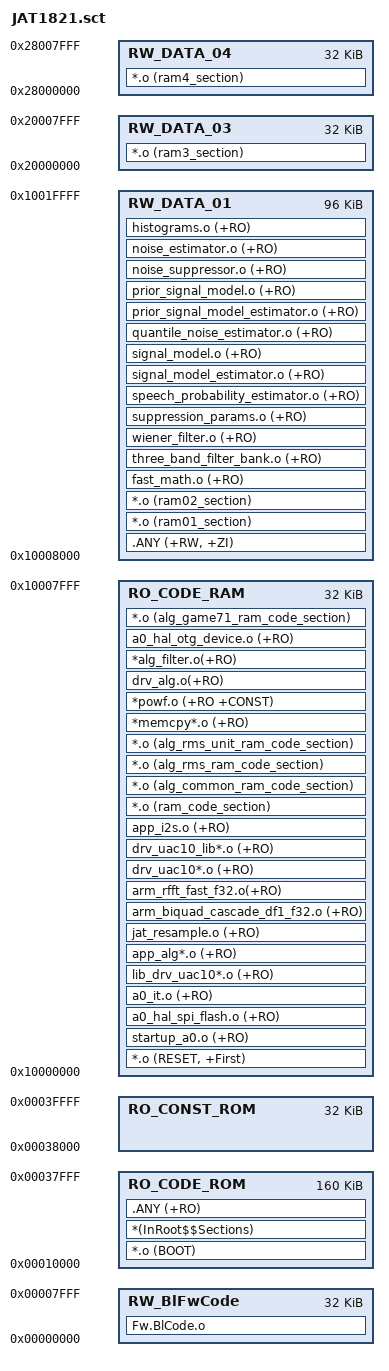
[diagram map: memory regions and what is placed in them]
; *************************************************************
; *** Scatter-Loading Description File generated by uVision ***
; *************************************************************

;;SCT的分配，需要和system_a0.c中的Cache配置相关，确认哪些部分需要Cache，哪些不需要Cache
;;LR_ROM0的地址是Flash起始地址
;;LR_ROM1的地址是接着LR_ROM0 (LR_ROM0_START + LR_ROM0_LEN)
;;LR_ROM2的地址是接着LR_ROM1 (LR_ROM1_START + LR_ROM1_LEN)
;;如果不需要Boot，直接使用用户代码启动，那么将LR_ROM0的起始地址改成0开始，LR_ROM1，LR_ROM2对应修改

LR_BlFwCode  0x00000000  0x8000
{
	RW_BlFwCode  0x00000000  0x8000
	{
		Fw.BlCode.o
	}
}

;;ROM第一部分，启动时入口处
LR_ROM0 0x00008000 0x00008000                                   ;; load region
{
    RO_CODE_RAM 0x10000000 0x00008000                           ;; execute region
    {;;Ram0中运行的代码段，启动的时候在Flash中运行，之后在Ram中运行
        *.o (RESET, +First)
		startup_a0.o (+RO)
        a0_hal_spi_flash.o (+RO)
        a0_it.o (+RO)

        lib_drv_uac10*.o (+RO)                  ;; 全部库文件中的函数
        app_alg*.o (+RO)
        jat_resample.o (+RO)
		arm_biquad_cascade_df1_f32.o (+RO)
		arm_rfft_fast_f32.o(+RO)
		
;		arm_bitreversal2.o(+RO)
;		arm_cfft_f32.o(+RO)
;		arm_cfft_radix8_f32.o(+RO)
;		arm_copy_f32.o(+RO)
;		arm_dot_prod_f32.o(+RO)
				
        drv_uac10*.o (+RO)
		drv_uac10_lib*.o (+RO)
        app_i2s.o (+RO)
        *.o (ram_code_section)
        *.o (alg_common_ram_code_section) 
		

		*.o (alg_rms_ram_code_section)
        *.o (alg_rms_unit_ram_code_section)
		
        *memcpy*.o (+RO)
		*powf.o (+RO +CONST)
         drv_alg.o(+RO)       
        *alg_filter.o(+RO)
		a0_hal_otg_device.o (+RO)
		;*.o (alg_dcblock_ram_code_section)
		*.o (alg_game71_ram_code_section)
		;*.o (alg_freqshift_ram_code_section)   

	}
}



;;ROM第二部分，直接Flash运行的
LR_ROM1 0x00010000 0x00028000                                  ;; load region
{
    ;;rom
	RO_CODE_ROM 0x00010000 0x00028000
	{;;Flash中的代码段，Cache范围内  ;HAL_SPIFC_CACHE_RANGE_SET();
        *.o (BOOT)
        *(InRoot$$Sections)
        .ANY (+RO)
		
		
		
	}
    ;;;ram
    RW_DATA_01 0x10008000 0x00018000
    {
        .ANY (+RW, +ZI)
        *.o (ram01_section)
        *.o (ram02_section)
		
		fast_math.o (+RO)
		three_band_filter_bank.o (+RO)
		wiener_filter.o (+RO)
		suppression_params.o (+RO)
		speech_probability_estimator.o (+RO)
		signal_model_estimator.o (+RO)
		signal_model.o (+RO)
		quantile_noise_estimator.o (+RO)
		prior_signal_model_estimator.o (+RO)
		prior_signal_model.o (+RO)
		noise_suppressor.o (+RO)
		noise_estimator.o (+RO)
		histograms.o (+RO)
		
    }
	
;    RW_DATA_02 0x20000000 0x00008000
;    {
;        ; __RAM1指定字段RAM
;		*.o (ram1_section)
;    }
;	
;	 RW_DATA_03 0x28000000 0x00008000
;    {
;        ; __RAM2指定字段RAM
;		*.o (ram2_section)
;    }

	RW_DATA_03 0x20000000 0x00008000
    {
        ; __RAM2指定字段RAM
		*.o (ram3_section)
    }
	RW_DATA_04 0x28000000 0x00008000
    {
        ; __RAM2指定字段RAM
		*.o (ram4_section)
    }
}


;ROM第三部分，表格数据段
LR_ROM2 0x00038000 0x00008000									;; load region
{
   RO_CONST_ROM 0x00038000 0x00008000
   {;;Flash中的数据段
		
;		.ANY (+RO)
;		enc.o (+RO)
;		wiener_filter.o (+RO)
;		three_band_filter_bank.o (+RO)
;		suppression_params.o (+RO)
;		speech_probability_estimator.o (+RO)
;		signal_model_estimator.o (+RO)
;		signal_model.o (+RO)
;		quantile_noise_estimator.o (+RO)
;		prior_signal_model_estimator.o (+RO)
;		prior_signal_model.o (+RO)
;		noise_suppressor.o (+RO)
;		noise_estimator.o (+RO)
;		histograms.o (+RO)
;		fast_math.o (+RO)
    }
}
